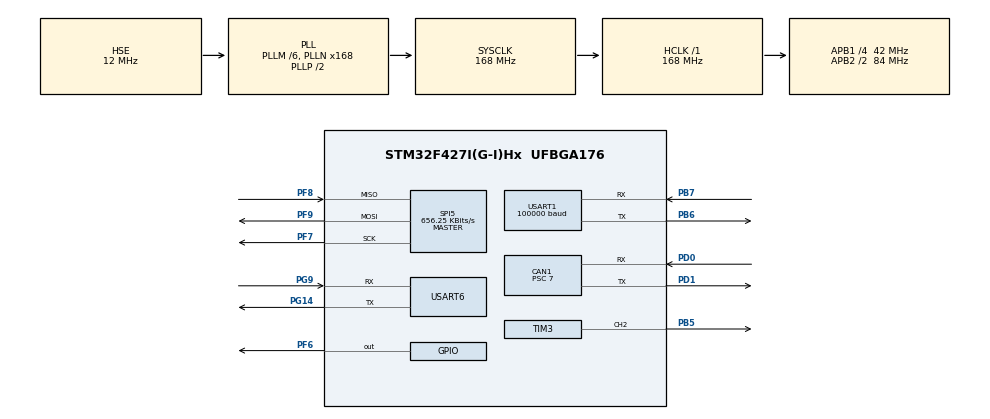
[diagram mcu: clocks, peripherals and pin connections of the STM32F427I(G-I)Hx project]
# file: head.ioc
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ADC1.Channel-0\#ChannelRegularConversion=ADC_CHANNEL_TEMPSENSOR
ADC1.NbrOfConversionFlag=1
ADC1.Rank-0\#ChannelRegularConversion=1
ADC1.SamplingTime-0\#ChannelRegularConversion=ADC_SAMPLETIME_3CYCLES
ADC1.master=1
CAN1.ABOM=ENABLE
CAN1.AWUM=ENABLE
CAN1.BS1=CAN_BS1_3TQ
CAN1.BS2=CAN_BS2_2TQ
CAN1.CalculateTimeQuantum=166.66666666666669
CAN1.NART=ENABLE
CAN1.Prescaler=7
Dma.Request0=USART1_RX
Dma.USART1_RX.0.Direction=DMA_PERIPH_TO_MEMORY
Dma.USART1_RX.0.FIFOMode=DMA_FIFOMODE_DISABLE
Dma.USART1_RX.0.Instance=DMA2_Stream2
Dma.USART1_RX.0.MemDataAlignment=DMA_MDATAALIGN_BYTE
Dma.USART1_RX.0.MemInc=DMA_MINC_ENABLE
Dma.USART1_RX.0.Mode=DMA_CIRCULAR
Dma.USART1_RX.0.PeriphDataAlignment=DMA_PDATAALIGN_BYTE
Dma.USART1_RX.0.PeriphInc=DMA_PINC_DISABLE
Dma.USART1_RX.0.Priority=DMA_PRIORITY_VERY_HIGH
FREERTOS.Tasks01=defaultTask,0,128,StartDefaultTask,Default,NULL,Dynamic,NULL,NULL;myTask02,-3,128,StartTask02,Default,NULL,Dynamic,NULL,NULL
Mcu.Family=STM32F4
Mcu.Name=STM32F427I(G-I)Hx
Mcu.Package=UFBGA176
NVIC.CAN1_RX0_IRQn=true\:0\:0\:false\:false\:true\:false\:true\:true
NVIC.DMA2_Stream2_IRQn=true\:0\:0\:false\:false\:true\:true\:false\:true
NVIC.PriorityGroup=NVIC_PRIORITYGROUP_4
NVIC.TIM2_IRQn=true\:0\:0\:false\:false\:true\:false\:true\:true
NVIC.TIM6_DAC_IRQn=true\:0\:0\:false\:false\:true\:false\:false\:true
NVIC.TimeBase=TIM6_DAC_IRQn
NVIC.TimeBaseIP=TIM6
NVIC.USART1_IRQn=true\:0\:0\:false\:false\:true\:false\:true\:true
NVIC.USART6_IRQn=true\:0\:0\:false\:false\:true\:false\:true\:true
PA13.Mode=Serial_Wire
PA13.Signal=SYS_JTMS-SWDIO
PA14.Mode=Serial_Wire
PA14.Signal=SYS_JTCK-SWCLK
PB5.Signal=S_TIM3_CH2
PB6.Mode=Asynchronous
PB6.Signal=USART1_TX
PB7.Mode=Asynchronous
PB7.Signal=USART1_RX
PD0.Mode=Master
PD0.Signal=CAN1_RX
PD1.Mode=Master
PD1.Signal=CAN1_TX
PF6.Signal=GPIO_Output
PF7.Mode=Full_Duplex_Master
PF7.Signal=SPI5_SCK
PF8.Mode=Full_Duplex_Master
PF8.Signal=SPI5_MISO
PF9.Mode=Full_Duplex_Master
PF9.Signal=SPI5_MOSI
PG14.Mode=Asynchronous
PG14.Signal=USART6_TX
PG9.Mode=Asynchronous
PG9.Signal=USART6_RX
PH0/OSC_IN.Mode=HSE-External-Oscillator
PH0/OSC_IN.Signal=RCC_OSC_IN
PH1/OSC_OUT.Mode=HSE-External-Oscillator
PH1/OSC_OUT.Signal=RCC_OSC_OUT
ProjectManager.HeapSize=0x200
ProjectManager.StackSize=0x400
ProjectManager.TargetToolchain=MDK-ARM V5.27
RCC.48MHZClocksFreq_Value=84000000
RCC.AHBFreq_Value=168000000
RCC.APB1CLKDivider=RCC_HCLK_DIV4
RCC.APB1Freq_Value=42000000
RCC.APB1TimFreq_Value=84000000
RCC.APB2CLKDivider=RCC_HCLK_DIV2
RCC.APB2Freq_Value=84000000
RCC.APB2TimFreq_Value=168000000
RCC.CortexFreq_Value=168000000
RCC.HCLKFreq_Value=168000000
RCC.HSE_VALUE=12000000
RCC.HSI_VALUE=16000000
RCC.LSE_VALUE=32768
RCC.PLLM=6
RCC.PLLN=168
RCC.PLLSourceVirtual=RCC_PLLSOURCE_HSE
RCC.SYSCLKFreq_VALUE=168000000
RCC.SYSCLKSource=RCC_SYSCLKSOURCE_PLLCLK
RCC.VCOOutputFreq_Value=336000000
SH.S_TIM3_CH2.0=TIM3_CH2,PWM Generation2 CH2
SPI5.BaudRatePrescaler=SPI_BAUDRATEPRESCALER_128
SPI5.CalculateBaudRate=656.25 KBits/s
SPI5.Direction=SPI_DIRECTION_2LINES
SPI5.Mode=SPI_MODE_MASTER
SPI5.VirtualType=VM_MASTER
TIM2.AutoReloadPreload=TIM_AUTORELOAD_PRELOAD_ENABLE
TIM2.Period=49
TIM2.Prescaler=8399
TIM3.Channel-PWM\ Generation2\ CH2=TIM_CHANNEL_2
TIM3.Period=4399
USART1.BaudRate=100000
USART1.VirtualMode=VM_ASYNC
USART6.VirtualMode=VM_ASYNC
VP_ADC1_TempSens_Input.Mode=IN-TempSens
VP_FREERTOS_VS_CMSIS_V1.Mode=CMSIS_V1
VP_SYS_VS_tim6.Mode=TIM6
VP_TIM2_VS_ClockSourceINT.Mode=Internal
VP_TIM3_VS_ClockSourceINT.Mode=Internal
board=custom

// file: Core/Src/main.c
/* USER CODE BEGIN Header */
/**
  ******************************************************************************
  * @file           : main.c
  * @brief          : Main program body
  ******************************************************************************
  * @attention
  *
  * <h2><center>&copy; Copyright (c) 2022 STMicroelectronics.
  * All rights reserved.</center></h2>
  *
  * This software component is licensed by ST under Ultimate Liberty license
  * SLA0044, the "License"; You may not use this file except in compliance with
  * the License. You may obtain a copy of the License at:
  *                             www.st.com/SLA0044
  *
  ******************************************************************************
  */
/* USER CODE END Header */
#include "main.h"
#include "cmsis_os.h"
#include "adc.h"
#include "can.h"
#include "dma.h"
#include "spi.h"
#include "tim.h"
#include "usart.h"
#include "gpio.h"

/* USER CODE BEGIN Includes */
#include "remoter.h"
#include "motor.h"
#include "IMU_Compensate.h"
#include "DJI_IMU.h"
/* USER CODE END Includes */

/* USER CODE BEGIN PV */
extern rc_info_t rc;
extern motor_measure_t ptr;

/* USER CODE END PV */

void SystemClock_Config(void);
void MX_FREERTOS_Init(void);

int main(void)
{

  /* MCU Configuration--------------------------------------------------------*/

  /* Reset of all peripherals, Initializes the Flash interface and the Systick. */
  HAL_Init();

  /* Configure the system clock */
  SystemClock_Config();

  /* Initialize all configured peripherals */
  MX_GPIO_Init();
  MX_DMA_Init();
  MX_CAN1_Init();
  MX_SPI5_Init();
  MX_USART1_UART_Init();
  MX_TIM2_Init();
  MX_USART6_UART_Init();
  MX_ADC1_Init();
  MX_TIM3_Init();
  /* USER CODE BEGIN 2 */
	dbus_uart_init();
	CAN_1_Filter_Config();
  HAL_TIM_Base_Start_IT(&htim2);
	Chassis_Init();
	DJI_IMUFUN.DJI_IMU_Init();

  /* USER CODE END 2 */

  /* Call init function for freertos objects (in freertos.c) */
  MX_FREERTOS_Init();
  /* Start scheduler */
  osKernelStart();

  /* We should never get here as control is now taken by the scheduler */
  /* Infinite loop */
  while (1)
  {

  }
}

void SystemClock_Config(void)
{
  RCC_OscInitTypeDef RCC_OscInitStruct = {0};
  RCC_ClkInitTypeDef RCC_ClkInitStruct = {0};

  /** Configure the main internal regulator output voltage
  */
  __HAL_RCC_PWR_CLK_ENABLE();
  __HAL_PWR_VOLTAGESCALING_CONFIG(PWR_REGULATOR_VOLTAGE_SCALE1);
  /** Initializes the RCC Oscillators according to the specified parameters
  * in the RCC_OscInitTypeDef structure.
  */
  RCC_OscInitStruct.OscillatorType = RCC_OSCILLATORTYPE_HSE;
  RCC_OscInitStruct.HSEState = RCC_HSE_ON;
  RCC_OscInitStruct.PLL.PLLState = RCC_PLL_ON;
  RCC_OscInitStruct.PLL.PLLSource = RCC_PLLSOURCE_HSE;
  RCC_OscInitStruct.PLL.PLLM = 6;
  RCC_OscInitStruct.PLL.PLLN = 168;
  RCC_OscInitStruct.PLL.PLLP = RCC_PLLP_DIV2;
  RCC_OscInitStruct.PLL.PLLQ = 4;
  if (HAL_RCC_OscConfig(&RCC_OscInitStruct) != HAL_OK)
  {
    Error_Handler();
  }
  /** Initializes the CPU, AHB and APB buses clocks
  */
  RCC_ClkInitStruct.ClockType = RCC_CLOCKTYPE_HCLK|RCC_CLOCKTYPE_SYSCLK
                              |RCC_CLOCKTYPE_PCLK1|RCC_CLOCKTYPE_PCLK2;
  RCC_ClkInitStruct.SYSCLKSource = RCC_SYSCLKSOURCE_PLLCLK;
  RCC_ClkInitStruct.AHBCLKDivider = RCC_SYSCLK_DIV1;
  RCC_ClkInitStruct.APB1CLKDivider = RCC_HCLK_DIV4;
  RCC_ClkInitStruct.APB2CLKDivider = RCC_HCLK_DIV2;

  if (HAL_RCC_ClockConfig(&RCC_ClkInitStruct, FLASH_LATENCY_5) != HAL_OK)
  {
    Error_Handler();
  }
}

void HAL_TIM_PeriodElapsedCallback(TIM_HandleTypeDef *htim)
{
  if (htim->Instance == TIM6) {
    HAL_IncTick();
  }
}

void Error_Handler(void)
{
}

/************************ (C) COPYRIGHT STMicroelectronics *****END OF FILE****/
